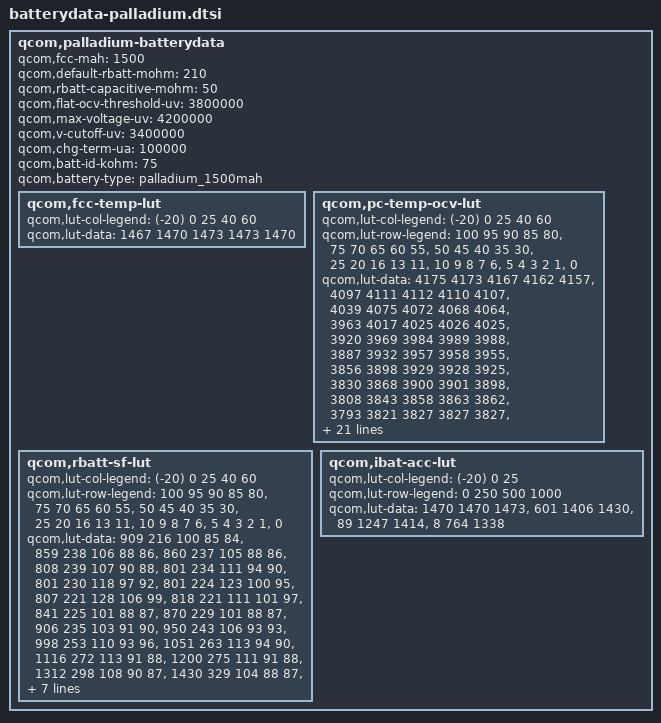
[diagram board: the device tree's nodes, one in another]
/* Copyright (c) 2013-2014, 2018 The Linux Foundation. All rights reserved.
 *
 * This program is free software; you can redistribute it and/or modify
 * it under the terms of the GNU General Public License version 2 and
 * only version 2 as published by the Free Software Foundation.
 *
 * This program is distributed in the hope that it will be useful,
 * but WITHOUT ANY WARRANTY; without even the implied warranty of
 * MERCHANTABILITY or FITNESS FOR A PARTICULAR PURPOSE.  See the
 * GNU General Public License for more details.
 */

qcom,palladium-batterydata {
	qcom,fcc-mah = <1500>;
	qcom,default-rbatt-mohm = <210>;
	qcom,rbatt-capacitive-mohm = <50>;
	qcom,flat-ocv-threshold-uv = <3800000>;
	qcom,max-voltage-uv = <4200000>;
	qcom,v-cutoff-uv = <3400000>;
	qcom,chg-term-ua = <100000>;
	qcom,batt-id-kohm = <75>;
	qcom,battery-type = "palladium_1500mah";

	qcom,fcc-temp-lut {
		qcom,lut-col-legend = <(-20) 0 25 40 60>;
		qcom,lut-data = <1467 1470 1473 1473 1470>;
	};

	qcom,pc-temp-ocv-lut {
		qcom,lut-col-legend = <(-20) 0 25 40 60>;
		qcom,lut-row-legend = <100 95 90 85 80>,
				<75 70 65 60 55>,
				<50 45 40 35 30>,
				<25 20 16 13 11>,
				<10 9 8 7 6>,
				<5 4 3 2 1>,
				<0>;
		qcom,lut-data = <4175 4173 4167 4162 4157>,
				<4097 4111 4112 4110 4107>,
				<4039 4075 4072 4068 4064>,
				<3963 4017 4025 4026 4025>,
				<3920 3969 3984 3989 3988>,
				<3887 3932 3957 3958 3955>,
				<3856 3898 3929 3928 3925>,
				<3830 3868 3900 3901 3898>,
				<3808 3843 3858 3863 3862>,
				<3793 3821 3827 3827 3827>,
				<3779 3803 3807 3808 3807>,
				<3768 3788 3792 3793 3792>,
				<3757 3779 3780 3780 3779>,
				<3746 3771 3772 3768 3768>,
				<3734 3762 3765 3759 3749>,
				<3722 3747 3753 3744 3730>,
				<3707 3721 3731 3722 3709>,
				<3693 3705 3704 3696 3683>,
				<3678 3698 3687 3678 3667>,
				<3664 3693 3683 3676 3665>,
				<3656 3690 3682 3675 3664>,
				<3646 3687 3681 3674 3662>,
				<3634 3683 3680 3672 3661>,
				<3618 3677 3676 3668 3656>,
				<3599 3667 3667 3655 3639>,
				<3573 3645 3638 3623 3603>,
				<3541 3607 3591 3575 3554>,
				<3496 3550 3528 3511 3490>,
				<3428 3469 3445 3423 3400>,
				<3312 3342 3308 3280 3250>,
				<3000 3000 3000 3000 3000>;
	};

	qcom,rbatt-sf-lut {
		qcom,lut-col-legend = <(-20) 0 25 40 60>;
		qcom,lut-row-legend = <100 95 90 85 80>,
				<75 70 65 60 55>,
				<50 45 40 35 30>,
				<25 20 16 13 11>,
				<10 9 8 7 6>,
				<5 4 3 2 1>,
				<0>;
		qcom,lut-data = <909 216 100 85 84>,
				<859 238 106 88 86>,
				<860 237 105 88 86>,
				<808 239 107 90 88>,
				<801 234 111 94 90>,
				<801 230 118 97 92>,
				<801 224 123 100 95>,
				<807 221 128 106 99>,
				<818 221 111 101 97>,
				<841 225 101 88 87>,
				<870 229 101 88 87>,
				<906 235 103 91 90>,
				<950 243 106 93 93>,
				<998 253 110 93 96>,
				<1051 263 113 94 90>,
				<1116 272 113 91 88>,
				<1200 275 111 91 88>,
				<1312 298 108 90 87>,
				<1430 329 104 88 87>,
				<1484 351 107 91 89>,
				<1446 345 110 93 90>,
				<1398 344 112 94 90>,
				<1466 358 115 96 91>,
				<1490 357 117 96 90>,
				<1589 365 117 94 89>,
				<1828 379 111 91 88>,
				<2151 399 111 93 91>,
				<2621 436 117 98 95>,
				<3404 496 130 106 100>,
				<8212 616 150 1906 134>,
				<135251 124940 59087 49820 29672>;
	};

	qcom,ibat-acc-lut {
		qcom,lut-col-legend = <(-20) 0 25>;
		qcom,lut-row-legend = <0 250 500 1000>;
		qcom,lut-data = <1470 1470 1473>,
				<601 1406 1430>,
				<89 1247 1414>,
				<8 764 1338>;
	};
};
